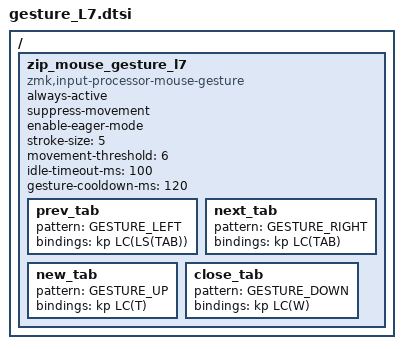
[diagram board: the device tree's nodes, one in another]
#include <dt-bindings/zmk/mouse-gesture.h>

/ {
    zip_mouse_gesture_l7: zip_mouse_gesture_l7 {
        compatible = "zmk,input-processor-mouse-gesture";
        #input-processor-cells = <0>;

        always-active;        // レイヤータップで遷移するため起動キー不要
        suppress-movement;    // このレイヤー中はカーソルを固定する
        enable-eager-mode;
        stroke-size = <5>;
        movement-threshold = <6>;
        idle-timeout-ms = <100>;
        gesture-cooldown-ms = <120>;

        // タブ操作
        prev_tab   { pattern = <GESTURE_LEFT>;  bindings = <&kp LC(LS(TAB))>; };
        next_tab   { pattern = <GESTURE_RIGHT>; bindings = <&kp LC(TAB)>;     };
        new_tab    { pattern = <GESTURE_UP>;    bindings = <&kp LC(T)>;       };
        close_tab  { pattern = <GESTURE_DOWN>;  bindings = <&kp LC(W)>;       };
    };
};
